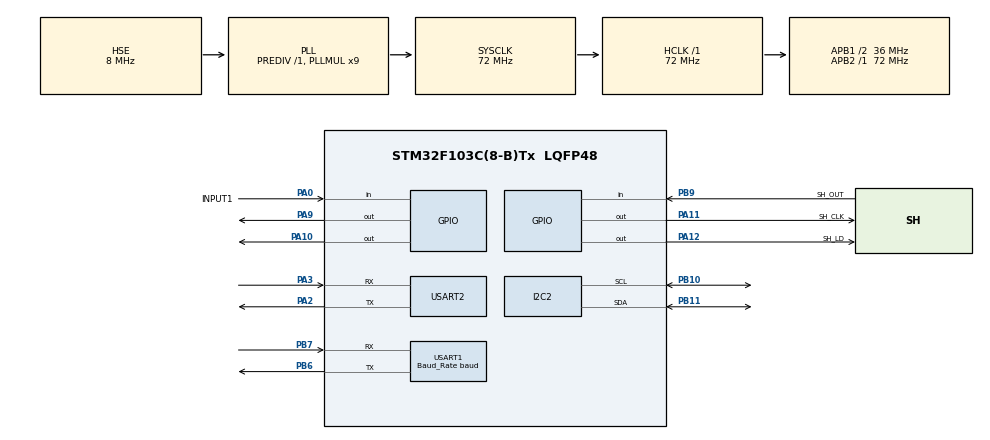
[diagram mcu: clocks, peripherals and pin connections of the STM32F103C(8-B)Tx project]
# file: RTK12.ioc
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Dma.Request0=USART1_RX
Dma.Request1=USART2_RX
Dma.USART1_RX.0.Direction=DMA_PERIPH_TO_MEMORY
Dma.USART1_RX.0.Instance=DMA1_Channel5
Dma.USART1_RX.0.MemDataAlignment=DMA_MDATAALIGN_BYTE
Dma.USART1_RX.0.MemInc=DMA_MINC_ENABLE
Dma.USART1_RX.0.Mode=DMA_CIRCULAR
Dma.USART1_RX.0.PeriphDataAlignment=DMA_PDATAALIGN_BYTE
Dma.USART1_RX.0.PeriphInc=DMA_PINC_DISABLE
Dma.USART1_RX.0.Priority=DMA_PRIORITY_LOW
Dma.USART2_RX.1.Direction=DMA_PERIPH_TO_MEMORY
Dma.USART2_RX.1.Instance=DMA1_Channel6
Dma.USART2_RX.1.MemDataAlignment=DMA_MDATAALIGN_BYTE
Dma.USART2_RX.1.MemInc=DMA_MINC_ENABLE
Dma.USART2_RX.1.Mode=DMA_CIRCULAR
Dma.USART2_RX.1.PeriphDataAlignment=DMA_PDATAALIGN_BYTE
Dma.USART2_RX.1.PeriphInc=DMA_PINC_DISABLE
Dma.USART2_RX.1.Priority=DMA_PRIORITY_LOW
Mcu.Family=STM32F1
Mcu.Name=STM32F103C(8-B)Tx
Mcu.Package=LQFP48
Mcu.UserConstants=Baud_Rate,691200
NVIC.DMA1_Channel5_IRQn=true\:0\:0\:false\:false\:true\:false\:true
NVIC.DMA1_Channel6_IRQn=true\:0\:0\:false\:false\:true\:false\:true
NVIC.PriorityGroup=NVIC_PRIORITYGROUP_4
NVIC.TIM1_BRK_IRQn=true\:0\:0\:false\:false\:true\:true\:true
NVIC.TIM1_CC_IRQn=true\:0\:0\:false\:false\:true\:true\:true
NVIC.TIM1_TRG_COM_IRQn=true\:0\:0\:false\:false\:true\:true\:true
NVIC.TIM1_UP_IRQn=true\:0\:0\:false\:false\:true\:true\:true
NVIC.TIM2_IRQn=true\:0\:0\:false\:false\:true\:true\:true
NVIC.TIM3_IRQn=true\:0\:0\:false\:false\:true\:true\:true
NVIC.USART1_IRQn=true\:0\:0\:false\:false\:true\:true\:true
NVIC.USART2_IRQn=true\:0\:0\:false\:false\:true\:true\:true
PA0-WKUP.GPIO_Label=INPUT1
PA0-WKUP.Signal=GPIO_Input
PA10.Signal=GPIO_Output
PA11.GPIO_Label=SH_CLK
PA11.Signal=GPIO_Output
PA12.GPIO_Label=SH_LD
PA12.PinState=GPIO_PIN_SET
PA12.Signal=GPIO_Output
PA13.Mode=Serial_Wire
PA13.Signal=SYS_JTMS-SWDIO
PA14.Mode=Serial_Wire
PA14.Signal=SYS_JTCK-SWCLK
PA2.Mode=Asynchronous
PA2.Signal=USART2_TX
PA3.Mode=Asynchronous
PA3.Signal=USART2_RX
PA9.Signal=GPIO_Output
PB10.Mode=I2C
PB10.Signal=I2C2_SCL
PB11.Mode=I2C
PB11.Signal=I2C2_SDA
PB6.Mode=Asynchronous
PB6.Signal=USART1_TX
PB7.Mode=Asynchronous
PB7.Signal=USART1_RX
PB9.GPIO_Label=SH_OUT
PB9.Signal=GPIO_Input
PD0-OSC_IN.Mode=HSE-External-Oscillator
PD0-OSC_IN.Signal=RCC_OSC_IN
PD1-OSC_OUT.Mode=HSE-External-Oscillator
PD1-OSC_OUT.Signal=RCC_OSC_OUT
ProjectManager.HeapSize=0x200
ProjectManager.StackSize=0x400
ProjectManager.TargetToolchain=MDK-ARM V5
RCC.AHBFreq_Value=72000000
RCC.APB1CLKDivider=RCC_HCLK_DIV2
RCC.APB1Freq_Value=36000000
RCC.APB1TimFreq_Value=72000000
RCC.APB2Freq_Value=72000000
RCC.APB2TimFreq_Value=72000000
RCC.HCLKFreq_Value=72000000
RCC.PLLMUL=RCC_PLL_MUL9
RCC.PLLSourceVirtual=RCC_PLLSOURCE_HSE
RCC.SYSCLKFreq_VALUE=72000000
RCC.SYSCLKSource=RCC_SYSCLKSOURCE_PLLCLK
RCC.USBFreq_Value=72000000
RTC.Date=3
RTC.Hours=14
RTC.Minutes=24
RTC.Month=RTC_MONTH_MARCH
RTC.WeekDay=RTC_WEEKDAY_THURSDAY
RTC.Year=22
TIM1.Period=1499
TIM1.Prescaler=47
TIM1.TIM_MasterOutputTrigger=TIM_TRGO_UPDATE
TIM2.Period=1499
TIM2.Prescaler=47999
TIM2.TIM_MasterOutputTrigger=TIM_TRGO_UPDATE
TIM3.Period=1
TIM3.Prescaler=46
TIM3.TIM_MasterOutputTrigger=TIM_TRGO_UPDATE
USART1.BaudRate=Baud_Rate
USART1.VirtualMode=VM_ASYNC
USART2.VirtualMode=VM_ASYNC
VP_RTC_No_RTC_Output.Mode=RTC_OUT_NO
VP_RTC_VS_RTC_Activate.Mode=RTC_Enabled
VP_TIM1_VS_ClockSourceINT.Mode=Internal
VP_TIM2_VS_ClockSourceINT.Mode=Internal
VP_TIM3_VS_ClockSourceINT.Mode=Internal
board=custom

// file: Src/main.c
/* USER CODE BEGIN Heade */
/**
  ******************************************************************************
  * @file           : main.c
  * @brief          : Main program body
  ******************************************************************************
  * @attention
  *
  * <h2><center>&copy; Copyright (c) 2022 STMicroelectronics.
  * All rights reserved.</center></h2>
  *
  * This software component is licensed by ST under BSD 3-Clause license,
  * the "License"; You may not use this file except in compliance with the
  * License. You may obtain a copy of the License at:
  *                        opensource.org/licenses/BSD-3-Clause
  *
  ******************************************************************************
  */
/* USER CODE END Header */

#include "main.h"
#include "dma.h"
#include "i2c.h"
#include "rtc.h"
#include "tim.h"
#include "usart.h"
#include "gpio.h"

/* USER CODE BEGIN Includes */
#include "Application_Interface.h"
/* USER CODE END Includes */

void SystemClock_Config(void);

int main(void)
{

  /* MCU Configuration--------------------------------------------------------*/

  /* Reset of all peripherals, Initializes the Flash interface and the Systick. */
  HAL_Init();

  /* Configure the system clock */
  SystemClock_Config();

  /* Initialize all configured peripherals */
  MX_GPIO_Init();
  MX_DMA_Init();
  MX_TIM1_Init();
  MX_USART1_UART_Init();
  MX_TIM2_Init();
  MX_TIM3_Init();
  MX_USART2_UART_Init();
  MX_I2C2_Init();
  MX_RTC_Init();
  /* USER CODE BEGIN 2 */
	Application_Init();
  /* USER CODE END 2 */

  /* Infinite loop */
  /* USER CODE BEGIN WHILE */
  while (1)
  {
		Application();
		//Hi Ahmed is inside
    /* USER CODE END WHILE */

  }
}

void SystemClock_Config(void)
{
  RCC_OscInitTypeDef RCC_OscInitStruct = {0};
  RCC_ClkInitTypeDef RCC_ClkInitStruct = {0};
  RCC_PeriphCLKInitTypeDef PeriphClkInit = {0};

  /** Initializes the CPU, AHB and APB busses clocks
  */
  RCC_OscInitStruct.OscillatorType = RCC_OSCILLATORTYPE_LSI|RCC_OSCILLATORTYPE_HSE;
  RCC_OscInitStruct.HSEState = RCC_HSE_ON;
  RCC_OscInitStruct.HSEPredivValue = RCC_HSE_PREDIV_DIV1;
  RCC_OscInitStruct.HSIState = RCC_HSI_ON;
  RCC_OscInitStruct.LSIState = RCC_LSI_ON;
  RCC_OscInitStruct.PLL.PLLState = RCC_PLL_ON;
  RCC_OscInitStruct.PLL.PLLSource = RCC_PLLSOURCE_HSE;
  RCC_OscInitStruct.PLL.PLLMUL = RCC_PLL_MUL9;
  if (HAL_RCC_OscConfig(&RCC_OscInitStruct) != HAL_OK)
  {
    Error_Handler();
  }
  /** Initializes the CPU, AHB and APB busses clocks
  */
  RCC_ClkInitStruct.ClockType = RCC_CLOCKTYPE_HCLK|RCC_CLOCKTYPE_SYSCLK
                              |RCC_CLOCKTYPE_PCLK1|RCC_CLOCKTYPE_PCLK2;
  RCC_ClkInitStruct.SYSCLKSource = RCC_SYSCLKSOURCE_PLLCLK;
  RCC_ClkInitStruct.AHBCLKDivider = RCC_SYSCLK_DIV1;
  RCC_ClkInitStruct.APB1CLKDivider = RCC_HCLK_DIV2;
  RCC_ClkInitStruct.APB2CLKDivider = RCC_HCLK_DIV1;

  if (HAL_RCC_ClockConfig(&RCC_ClkInitStruct, FLASH_LATENCY_2) != HAL_OK)
  {
    Error_Handler();
  }
  PeriphClkInit.PeriphClockSelection = RCC_PERIPHCLK_RTC;
  PeriphClkInit.RTCClockSelection = RCC_RTCCLKSOURCE_LSI;
  if (HAL_RCCEx_PeriphCLKConfig(&PeriphClkInit) != HAL_OK)
  {
    Error_Handler();
  }
}

void Error_Handler(void)
{
}

/************************ (C) COPYRIGHT STMicroelectronics *****END OF FILE****/
